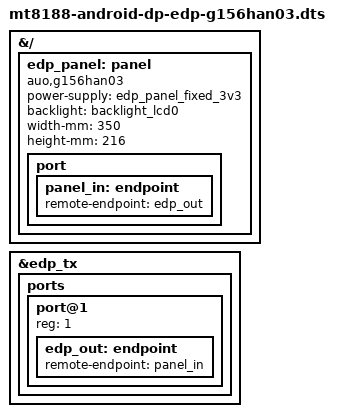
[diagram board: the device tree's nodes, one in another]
// SPDX-License-Identifier: GPL-2.0
/*
 * Copyright (c) 2025 BayLibre, SAS.
 * Author: Vitor Sato Eschholz <vsatoes@baylibre.com>
 */

/dts-v1/;
/plugin/;

#include "mt8188-android-edp.dtsi"
#include "mt8188-android-dp.dtsi"

&{/} {
	edp_panel: panel {
		compatible = "auo,g156han03";
		power-supply = <&edp_panel_fixed_3v3>;
		backlight = <&backlight_lcd0>;
		width-mm = <350>;
		height-mm = <216>;
		status = "okay";

		port {
			panel_in: endpoint {
				remote-endpoint = <&edp_out>;
			};
		};
	};
};

&edp_tx {
	ports {
		#address-cells = <1>;
		#size-cells = <0>;

		port@1 {
			reg = <1>;
			edp_out: endpoint {
				remote-endpoint = <&panel_in>;
			};
		};
	};
};
